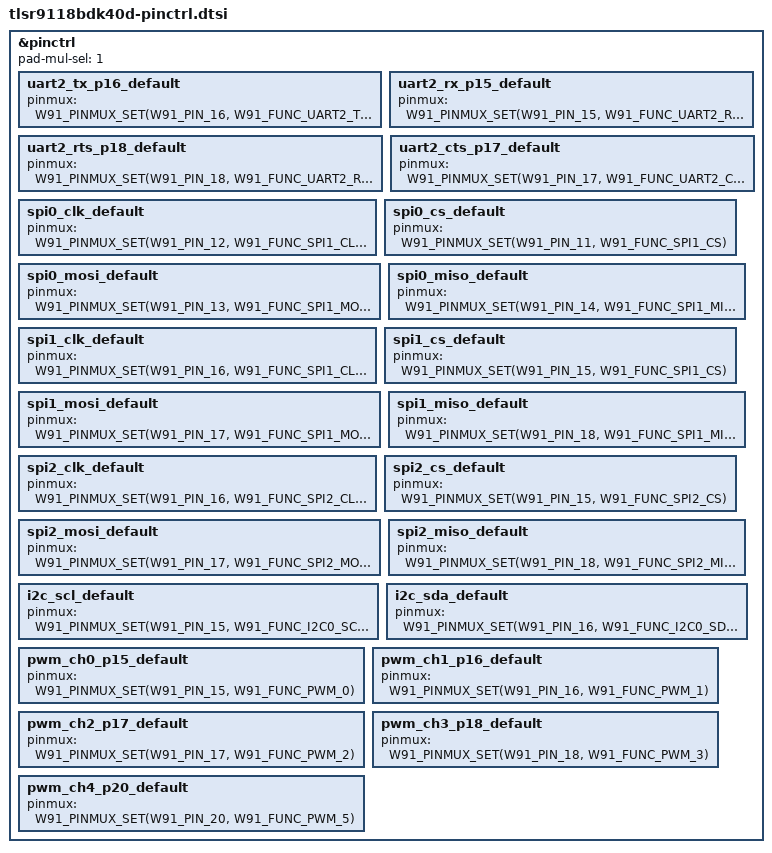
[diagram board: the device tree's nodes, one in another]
/*
 * Copyright (c) 2023 Telink Semiconductor
 *
 * SPDX-License-Identifier: Apache-2.0
 */

#include <zephyr/dt-bindings/pinctrl/w91-pinctrl.h>

&pinctrl {
	/* Set pad-mul-sel register value.
	 * Note: Pins functions below (pinmux = <...>) depend on this value.
	 */
	pad-mul-sel = <1>;

	/* UART2: TX(P16), RX(P15), RTS(P18), CTS(P17) */

	uart2_tx_p16_default: uart2_tx_p16_default {
		pinmux = <W91_PINMUX_SET(W91_PIN_16, W91_FUNC_UART2_TXD)>;
	};
	uart2_rx_p15_default: uart2_rx_p15_default {
		pinmux = <W91_PINMUX_SET(W91_PIN_15, W91_FUNC_UART2_RXD)>;
	};
	uart2_rts_p18_default: uart2_rts_p18_default {
		pinmux = <W91_PINMUX_SET(W91_PIN_18, W91_FUNC_UART2_RTS)>;
	};
	uart2_cts_p17_default: uart2_cts_p17_default {
		pinmux = <W91_PINMUX_SET(W91_PIN_17, W91_FUNC_UART2_CTS)>;
	};

	/* ATCSPI0 */
	spi0_clk_default: spi0_clk_default {
		pinmux = <W91_PINMUX_SET(W91_PIN_12, W91_FUNC_SPI1_CLK)>;
	};
	spi0_cs_default: spi0_cs_default {
		pinmux = <W91_PINMUX_SET(W91_PIN_11, W91_FUNC_SPI1_CS)>;
	};
	spi0_mosi_default: spi0_mosi_default {
		pinmux = <W91_PINMUX_SET(W91_PIN_13, W91_FUNC_SPI1_MOSI)>;
	};
	spi0_miso_default: spi0_miso_default {
		pinmux = <W91_PINMUX_SET(W91_PIN_14, W91_FUNC_SPI1_MISO)>;
	};

	/* ATCSPI1 */
	spi1_clk_default: spi1_clk_default {
		pinmux = <W91_PINMUX_SET(W91_PIN_16, W91_FUNC_SPI1_CLK)>;
	};
	spi1_cs_default: spi1_cs_default {
		pinmux = <W91_PINMUX_SET(W91_PIN_15, W91_FUNC_SPI1_CS)>;
	};
	spi1_mosi_default: spi1_mosi_default {
		pinmux = <W91_PINMUX_SET(W91_PIN_17, W91_FUNC_SPI1_MOSI)>;
	};
	spi1_miso_default: spi1_miso_default {
		pinmux = <W91_PINMUX_SET(W91_PIN_18, W91_FUNC_SPI1_MISO)>;
	};

	/* ATCSPI2 */
	spi2_clk_default: spi2_clk_default {
		pinmux = <W91_PINMUX_SET(W91_PIN_16, W91_FUNC_SPI2_CLK)>;
	};
	spi2_cs_default: spi2_cs_default {
		pinmux = <W91_PINMUX_SET(W91_PIN_15, W91_FUNC_SPI2_CS)>;
	};
	spi2_mosi_default: spi2_mosi_default {
		pinmux = <W91_PINMUX_SET(W91_PIN_17, W91_FUNC_SPI2_MOSI)>;
	};
	spi2_miso_default: spi2_miso_default {
		pinmux = <W91_PINMUX_SET(W91_PIN_18, W91_FUNC_SPI2_MISO)>;
	};
/*
SPI2 pinmux
	MUX("clk", 3, 5),
	MUX("cs",  2, 5),
	MUX("mosi",4, 5),
	MUX("miso",5, 5),
	MUX("wp",  6, 5),
	MUX("hold",7, 5),

	MUX("clk", 16, 5),
	MUX("cs",  15, 5),
	MUX("mosi",17, 5),
	MUX("miso",18, 5),
	MUX("wp",19, 5),
	MUX("hold",20, 5),

	MUX("clk", 22, 5),
	MUX("cs",  21, 5),
	MUX("mosi",23, 5),
	MUX("miso",24, 5),
*/
	i2c_scl_default: i2c_scl_default {
		pinmux = <W91_PINMUX_SET(W91_PIN_15, W91_FUNC_I2C0_SCL)>;
	};
	i2c_sda_default: i2c_sda_default {
		pinmux = <W91_PINMUX_SET(W91_PIN_16, W91_FUNC_I2C0_SDA)>;
	};
	/* PWM Channel 0 (P15) */

	pwm_ch0_p15_default: pwm_ch0_p15_default {
		pinmux = <W91_PINMUX_SET(W91_PIN_15, W91_FUNC_PWM_0)>;
	};
	/* PWM Channel 1 (P16) */

	pwm_ch1_p16_default: pwm_ch1_p16_default {
		pinmux = <W91_PINMUX_SET(W91_PIN_16, W91_FUNC_PWM_1)>;
	};
	/* PWM Channel 2 (P17) */

	pwm_ch2_p17_default: pwm_ch2_p17_default {
		pinmux = <W91_PINMUX_SET(W91_PIN_17, W91_FUNC_PWM_2)>;
	};
	/* PWM Channel 3 (P18) */

	pwm_ch3_p18_default: pwm_ch3_p18_default {
		pinmux = <W91_PINMUX_SET(W91_PIN_18, W91_FUNC_PWM_3)>;
	};
	/* PWM Channel 4 (P20) */

	pwm_ch4_p20_default: pwm_ch4_p20_default {
		pinmux = <W91_PINMUX_SET(W91_PIN_20, W91_FUNC_PWM_5)>;
	};
};
